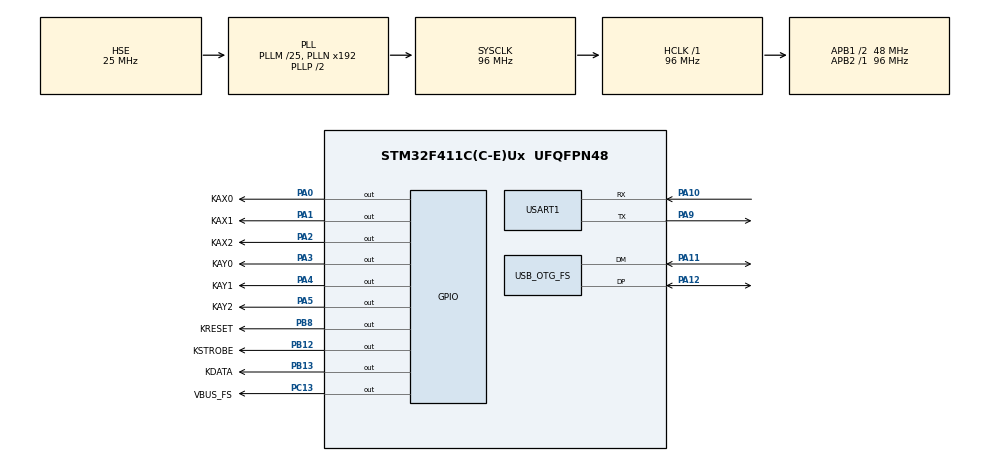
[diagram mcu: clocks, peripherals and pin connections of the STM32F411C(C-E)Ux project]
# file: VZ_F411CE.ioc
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Mcu.Family=STM32F4
Mcu.Name=STM32F411C(C-E)Ux
Mcu.Package=UFQFPN48
NVIC.OTG_FS_IRQn=true\:0\:0\:false\:false\:true\:true\:true
NVIC.PriorityGroup=NVIC_PRIORITYGROUP_4
NVIC.USART1_IRQn=true\:0\:0\:false\:false\:true\:true\:true
PA0-WKUP.GPIO_Label=KAX0
PA0-WKUP.Signal=GPIO_Output
PA1.GPIO_Label=KAX1
PA1.Signal=GPIO_Output
PA10.Mode=Asynchronous
PA10.Signal=USART1_RX
PA11.Mode=Host_Only
PA11.Signal=USB_OTG_FS_DM
PA12.Mode=Host_Only
PA12.Signal=USB_OTG_FS_DP
PA2.GPIO_Label=KAX2
PA2.Signal=GPIO_Output
PA3.GPIO_Label=KAY0
PA3.Signal=GPIO_Output
PA4.GPIO_Label=KAY1
PA4.Signal=GPIO_Output
PA5.GPIO_Label=KAY2
PA5.Signal=GPIO_Output
PA9.Mode=Asynchronous
PA9.Signal=USART1_TX
PB12.GPIO_Label=KSTROBE
PB12.Signal=GPIO_Output
PB13.GPIO_Label=KDATA
PB13.Signal=GPIO_Output
PB8.GPIO_Label=KRESET
PB8.Signal=GPIO_Output
PC13-ANTI_TAMP.GPIO_Label=VBUS_FS
PC13-ANTI_TAMP.Signal=GPIO_Output
PH0\ -\ OSC_IN.Mode=HSE-External-Oscillator
PH0\ -\ OSC_IN.Signal=RCC_OSC_IN
PH1\ -\ OSC_OUT.Mode=HSE-External-Oscillator
PH1\ -\ OSC_OUT.Signal=RCC_OSC_OUT
ProjectManager.HeapSize=0x400
ProjectManager.StackSize=0x800
ProjectManager.TargetToolchain=STM32CubeIDE
RCC.48MHZClocksFreq_Value=48000000
RCC.AHBFreq_Value=96000000
RCC.APB1CLKDivider=RCC_HCLK_DIV2
RCC.APB1Freq_Value=48000000
RCC.APB1TimFreq_Value=96000000
RCC.APB2Freq_Value=96000000
RCC.APB2TimFreq_Value=96000000
RCC.CortexFreq_Value=96000000
RCC.HCLKFreq_Value=96000000
RCC.HSE_VALUE=25000000
RCC.HSI_VALUE=16000000
RCC.LSE_VALUE=32768
RCC.PLLM=25
RCC.SYSCLKFreq_VALUE=96000000
RCC.SYSCLKSource=RCC_SYSCLKSOURCE_PLLCLK
RCC.VCOOutputFreq_Value=192000000
USART1.VirtualMode=VM_ASYNC
USB_HOST.BSP.number=1
USB_HOST.USBH_HandleTypeDef=hUsbHostFS
USB_HOST.VirtualModeFS=Hid
USB_HOST0.BSP.STBoard=false
USB_HOST0.BSP.api=Unknown
USB_HOST0.BSP.i2caddr=0
USB_HOST0.BSP.instance=PC13-ANTI_TAMP
USB_HOST0.BSP.ip=GPIO
USB_HOST0.BSP.mode=Output
USB_HOST0.BSP.name=Drive_VBUS_FS
USB_HOST0.BSP.solution=PC13-ANTI_TAMP
USB_OTG_FS.VirtualMode=Host_Only
USB_OTG_FS.phy_itface=HCD_PHY_EMBEDDED
VP_USB_HOST_VS_USB_HOST_HID_FS.Mode=HID_FS
board=custom

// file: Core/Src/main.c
/* USER CODE BEGIN Header */
/**
  ******************************************************************************
  * @file           : main.c
  * @brief          : Main program body
  ******************************************************************************
  * @attention
  *
  * <h2><center>&copy; Copyright (c) 2021 STMicroelectronics.
  * All rights reserved.</center></h2>
  *
  * This software component is licensed by ST under BSD 3-Clause license,
  * the "License"; You may not use this file except in compliance with the
  * License. You may obtain a copy of the License at:
  *                        opensource.org/licenses/BSD-3-Clause
  *
  ******************************************************************************
  */
/* USER CODE END Header */
#include "main.h"
#include "usb_host.h"

/* USER CODE BEGIN Includes */
#include "usbh_core.h"
#include "usbh_hid_keybd.h"
#include "matrix_keys.h"
/* USER CODE END Includes */

UART_HandleTypeDef huart1;

void SystemClock_Config(void);
static void MX_GPIO_Init(void);
static void MX_USART1_UART_Init(void);
void MX_USB_HOST_Process(void);

/* USER CODE BEGIN 0 */
void USBH_HID_EventCallback(USBH_HandleTypeDef *phost)
{
	HID_TypeTypeDef hidType = USBH_HID_GetDeviceType(phost);
	if (hidType == HID_KEYBOARD)
	{
		HID_KEYBD_Info_TypeDef *ki = USBH_HID_GetKeybdInfo(phost);
		switchUsbKeys(&ki->keys[0], ki->lshift || ki->rshift, ki->lctrl || ki->rctrl);
	}
}

/* USER CODE END 0 */

int main(void)
{

  /* MCU Configuration--------------------------------------------------------*/

  /* Reset of all peripherals, Initializes the Flash interface and the Systick. */
  HAL_Init();

  /* Configure the system clock */
  SystemClock_Config();

  /* Initialize all configured peripherals */
  MX_GPIO_Init();
  MX_USB_HOST_Init();
  MX_USART1_UART_Init();
  /* USER CODE BEGIN 2 */

  MT8816_Reset();

  /* USER CODE END 2 */

  /* Infinite loop */
  while (1)
  {
    MX_USB_HOST_Process();

    /* USER CODE BEGIN 3 */
    sendSequence();
  }
  /* USER CODE END 3 */
}

void SystemClock_Config(void)
{
  RCC_OscInitTypeDef RCC_OscInitStruct = {0};
  RCC_ClkInitTypeDef RCC_ClkInitStruct = {0};

  /** Configure the main internal regulator output voltage
  */
  __HAL_RCC_PWR_CLK_ENABLE();
  __HAL_PWR_VOLTAGESCALING_CONFIG(PWR_REGULATOR_VOLTAGE_SCALE1);
  /** Initializes the RCC Oscillators according to the specified parameters
  * in the RCC_OscInitTypeDef structure.
  */
  RCC_OscInitStruct.OscillatorType = RCC_OSCILLATORTYPE_HSE;
  RCC_OscInitStruct.HSEState = RCC_HSE_ON;
  RCC_OscInitStruct.PLL.PLLState = RCC_PLL_ON;
  RCC_OscInitStruct.PLL.PLLSource = RCC_PLLSOURCE_HSE;
  RCC_OscInitStruct.PLL.PLLM = 25;
  RCC_OscInitStruct.PLL.PLLN = 192;
  RCC_OscInitStruct.PLL.PLLP = RCC_PLLP_DIV2;
  RCC_OscInitStruct.PLL.PLLQ = 4;
  if (HAL_RCC_OscConfig(&RCC_OscInitStruct) != HAL_OK)
  {
    Error_Handler();
  }
  /** Initializes the CPU, AHB and APB buses clocks
  */
  RCC_ClkInitStruct.ClockType = RCC_CLOCKTYPE_HCLK|RCC_CLOCKTYPE_SYSCLK
                              |RCC_CLOCKTYPE_PCLK1|RCC_CLOCKTYPE_PCLK2;
  RCC_ClkInitStruct.SYSCLKSource = RCC_SYSCLKSOURCE_PLLCLK;
  RCC_ClkInitStruct.AHBCLKDivider = RCC_SYSCLK_DIV1;
  RCC_ClkInitStruct.APB1CLKDivider = RCC_HCLK_DIV2;
  RCC_ClkInitStruct.APB2CLKDivider = RCC_HCLK_DIV1;

  if (HAL_RCC_ClockConfig(&RCC_ClkInitStruct, FLASH_LATENCY_3) != HAL_OK)
  {
    Error_Handler();
  }
}

static void MX_USART1_UART_Init(void)
{

  huart1.Instance = USART1;
  huart1.Init.BaudRate = 115200;
  huart1.Init.WordLength = UART_WORDLENGTH_8B;
  huart1.Init.StopBits = UART_STOPBITS_1;
  huart1.Init.Parity = UART_PARITY_NONE;
  huart1.Init.Mode = UART_MODE_TX_RX;
  huart1.Init.HwFlowCtl = UART_HWCONTROL_NONE;
  huart1.Init.OverSampling = UART_OVERSAMPLING_16;
  if (HAL_UART_Init(&huart1) != HAL_OK)
  {
    Error_Handler();
  }

}

static void MX_GPIO_Init(void)
{
  GPIO_InitTypeDef GPIO_InitStruct = {0};

  /* GPIO Ports Clock Enable */
  __HAL_RCC_GPIOC_CLK_ENABLE();
  __HAL_RCC_GPIOH_CLK_ENABLE();
  __HAL_RCC_GPIOA_CLK_ENABLE();
  __HAL_RCC_GPIOB_CLK_ENABLE();

  /*Configure GPIO pin Output Level */
  HAL_GPIO_WritePin(VBUS_FS_GPIO_Port, VBUS_FS_Pin, GPIO_PIN_RESET);

  /*Configure GPIO pin Output Level */
  HAL_GPIO_WritePin(GPIOA, KAX0_Pin|KAX1_Pin|KAX2_Pin|KAY0_Pin
                          |KAY1_Pin|KAY2_Pin, GPIO_PIN_RESET);

  /*Configure GPIO pin Output Level */
  HAL_GPIO_WritePin(GPIOB, KSTROBE_Pin|KDATA_Pin|KRESET_Pin, GPIO_PIN_RESET);

  /*Configure GPIO pin : VBUS_FS_Pin */
  GPIO_InitStruct.Pin = VBUS_FS_Pin;
  GPIO_InitStruct.Mode = GPIO_MODE_OUTPUT_PP;
  GPIO_InitStruct.Pull = GPIO_NOPULL;
  GPIO_InitStruct.Speed = GPIO_SPEED_FREQ_LOW;
  HAL_GPIO_Init(VBUS_FS_GPIO_Port, &GPIO_InitStruct);

  /*Configure GPIO pins : KAX0_Pin KAX1_Pin KAX2_Pin KAY0_Pin
                           KAY1_Pin KAY2_Pin */
  GPIO_InitStruct.Pin = KAX0_Pin|KAX1_Pin|KAX2_Pin|KAY0_Pin
                          |KAY1_Pin|KAY2_Pin;
  GPIO_InitStruct.Mode = GPIO_MODE_OUTPUT_PP;
  GPIO_InitStruct.Pull = GPIO_NOPULL;
  GPIO_InitStruct.Speed = GPIO_SPEED_FREQ_LOW;
  HAL_GPIO_Init(GPIOA, &GPIO_InitStruct);

  /*Configure GPIO pins : KSTROBE_Pin KDATA_Pin KRESET_Pin */
  GPIO_InitStruct.Pin = KSTROBE_Pin|KDATA_Pin|KRESET_Pin;
  GPIO_InitStruct.Mode = GPIO_MODE_OUTPUT_PP;
  GPIO_InitStruct.Pull = GPIO_NOPULL;
  GPIO_InitStruct.Speed = GPIO_SPEED_FREQ_LOW;
  HAL_GPIO_Init(GPIOB, &GPIO_InitStruct);

}

void Error_Handler(void)
{
  __disable_irq();
  while (1)
  {
  }
}

/************************ (C) COPYRIGHT STMicroelectronics *****END OF FILE****/
